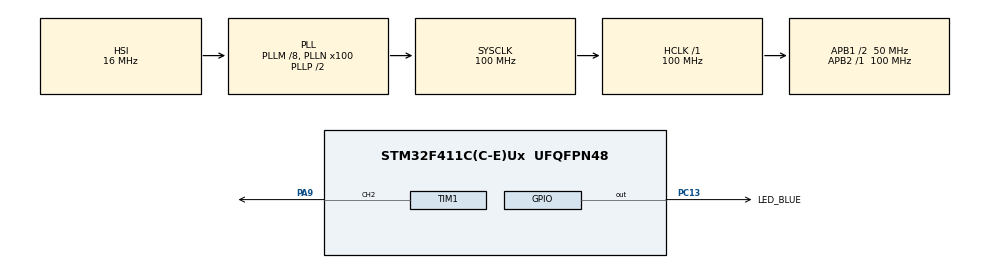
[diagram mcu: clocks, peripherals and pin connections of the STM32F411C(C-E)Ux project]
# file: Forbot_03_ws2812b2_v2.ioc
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Dma.Request0=TIM1_CH2
Dma.TIM1_CH2.0.Direction=DMA_MEMORY_TO_PERIPH
Dma.TIM1_CH2.0.FIFOMode=DMA_FIFOMODE_DISABLE
Dma.TIM1_CH2.0.Instance=DMA2_Stream2
Dma.TIM1_CH2.0.MemDataAlignment=DMA_MDATAALIGN_HALFWORD
Dma.TIM1_CH2.0.MemInc=DMA_MINC_ENABLE
Dma.TIM1_CH2.0.Mode=DMA_NORMAL
Dma.TIM1_CH2.0.PeriphDataAlignment=DMA_PDATAALIGN_HALFWORD
Dma.TIM1_CH2.0.PeriphInc=DMA_PINC_DISABLE
Dma.TIM1_CH2.0.Priority=DMA_PRIORITY_LOW
Mcu.Family=STM32F4
Mcu.Name=STM32F411C(C-E)Ux
Mcu.Package=UFQFPN48
NVIC.DMA2_Stream2_IRQn=true\:0\:0\:false\:false\:true\:false\:true
NVIC.PriorityGroup=NVIC_PRIORITYGROUP_4
PA9.Signal=S_TIM1_CH2
PC13-ANTI_TAMP.GPIO_Label=LED_BLUE
PC13-ANTI_TAMP.Signal=GPIO_Output
ProjectManager.HeapSize=0x200
ProjectManager.StackSize=0x400
ProjectManager.TargetToolchain=STM32CubeIDE
RCC.48MHZClocksFreq_Value=50000000
RCC.AHBFreq_Value=100000000
RCC.APB1CLKDivider=RCC_HCLK_DIV2
RCC.APB1Freq_Value=50000000
RCC.APB1TimFreq_Value=100000000
RCC.APB2Freq_Value=100000000
RCC.APB2TimFreq_Value=100000000
RCC.CortexFreq_Value=100000000
RCC.HCLKFreq_Value=100000000
RCC.HSE_VALUE=25000000
RCC.HSI_VALUE=16000000
RCC.LSE_VALUE=32768
RCC.PLLM=8
RCC.PLLN=100
RCC.SYSCLKFreq_VALUE=100000000
RCC.SYSCLKSource=RCC_SYSCLKSOURCE_PLLCLK
RCC.VCOOutputFreq_Value=200000000
SH.S_TIM1_CH2.0=TIM1_CH2,PWM Generation2 CH2
TIM1.Channel-PWM\ Generation2\ CH2=TIM_CHANNEL_2
TIM1.Period=124
VP_TIM1_VS_ClockSourceINT.Mode=Internal
board=custom

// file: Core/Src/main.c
/* USER CODE BEGIN Header */
/**
  ******************************************************************************
  * @file           : main.c
  * @brief          : Main program body
  ******************************************************************************
  * @attention
  *
  * Copyright (c) 2021 STMicroelectronics.
  * All rights reserved.
  *
  * This software is licensed under terms that can be found in the LICENSE file
  * in the root directory of this software component.
  * If no LICENSE file comes with this software, it is provided AS-IS.
  *
  ******************************************************************************
  */
/* USER CODE END Header */
#include "main.h"
#include "dma.h"
#include "tim.h"
#include "gpio.h"

/* USER CODE BEGIN Includes */

#include <stdlib.h>
#include "ws2812b.h"

/* USER CODE END Includes */

void SystemClock_Config(void);

int main(void)
{

  /* MCU Configuration--------------------------------------------------------*/

  /* Reset of all peripherals, Initializes the Flash interface and the Systick. */
  HAL_Init();

  /* Configure the system clock */
  SystemClock_Config();

  /* Initialize all configured peripherals */
  MX_GPIO_Init();
  MX_DMA_Init();
  MX_TIM1_Init();
  /* USER CODE BEGIN 2 */

//  HAL_TIM_Base_Start(&htim1);
// FUNKCJA TESTOWA
//  HAL_StatusTypeDef statusDMA;
//  uint16_t test[40 + 16 * 24 + 1] = {0};
//  // Zerowanie kolorów wszystkich diod
//  for (int i = 0; i < 16 * 24; i++)
//    test[40 + i] = 32;
//  // Włącz jedną diodę
//  test[40] = 64;
//  // Stan wysoki na końcu
//  test[40 + 16 * 24] = 100;
//  statusDMA = HAL_TIM_PWM_Start_DMA(&htim1, TIM_CHANNEL_2, &test, sizeof(test));
//  statusDMA = statusDMA;

  ws2812b_init();
  /* USER CODE END 2 */

  /* Infinite loop */
  /* USER CODE BEGIN WHILE */
  while (1)
  {
	  uint8_t r = 0;
	  uint8_t g = 0;
	  uint8_t b = 200;

	  for (int led = 0; led < 13; led++) {
	    ws2812b_set_color(led, r, g, b);
	    ws2812b_update();
	    HAL_Delay(300);
	  }

    /* USER CODE END WHILE */

  }
}

void SystemClock_Config(void)
{
  RCC_OscInitTypeDef RCC_OscInitStruct = {0};
  RCC_ClkInitTypeDef RCC_ClkInitStruct = {0};

  /** Configure the main internal regulator output voltage
  */
  __HAL_RCC_PWR_CLK_ENABLE();
  __HAL_PWR_VOLTAGESCALING_CONFIG(PWR_REGULATOR_VOLTAGE_SCALE1);
  /** Initializes the RCC Oscillators according to the specified parameters
  * in the RCC_OscInitTypeDef structure.
  */
  RCC_OscInitStruct.OscillatorType = RCC_OSCILLATORTYPE_HSI;
  RCC_OscInitStruct.HSIState = RCC_HSI_ON;
  RCC_OscInitStruct.HSICalibrationValue = RCC_HSICALIBRATION_DEFAULT;
  RCC_OscInitStruct.PLL.PLLState = RCC_PLL_ON;
  RCC_OscInitStruct.PLL.PLLSource = RCC_PLLSOURCE_HSI;
  RCC_OscInitStruct.PLL.PLLM = 8;
  RCC_OscInitStruct.PLL.PLLN = 100;
  RCC_OscInitStruct.PLL.PLLP = RCC_PLLP_DIV2;
  RCC_OscInitStruct.PLL.PLLQ = 4;
  if (HAL_RCC_OscConfig(&RCC_OscInitStruct) != HAL_OK)
  {
    Error_Handler();
  }
  /** Initializes the CPU, AHB and APB buses clocks
  */
  RCC_ClkInitStruct.ClockType = RCC_CLOCKTYPE_HCLK|RCC_CLOCKTYPE_SYSCLK
                              |RCC_CLOCKTYPE_PCLK1|RCC_CLOCKTYPE_PCLK2;
  RCC_ClkInitStruct.SYSCLKSource = RCC_SYSCLKSOURCE_PLLCLK;
  RCC_ClkInitStruct.AHBCLKDivider = RCC_SYSCLK_DIV1;
  RCC_ClkInitStruct.APB1CLKDivider = RCC_HCLK_DIV2;
  RCC_ClkInitStruct.APB2CLKDivider = RCC_HCLK_DIV1;

  if (HAL_RCC_ClockConfig(&RCC_ClkInitStruct, FLASH_LATENCY_3) != HAL_OK)
  {
    Error_Handler();
  }
}

void Error_Handler(void)
{
  __disable_irq();
  while (1)
  {
  }
}
